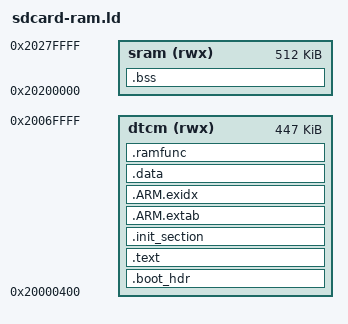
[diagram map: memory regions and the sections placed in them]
/****************************************************************************
 * boards/arm/imxrt/ccx/scripts/sdcard-ram.ld
 *
 * Licensed to the Apache Software Foundation (ASF) under one or more
 * contributor license agreements.  See the NOTICE file distributed with
 * this work for additional information regarding copyright ownership.  The
 * ASF licenses this file to you under the Apache License, Version 2.0 (the
 * "License"); you may not use this file except in compliance with the
 * License.  You may obtain a copy of the License at
 *
 *   http://www.apache.org/licenses/LICENSE-2.0
 *
 * Unless required by applicable law or agreed to in writing, software
 * distributed under the License is distributed on an "AS IS" BASIS, WITHOUT
 * WARRANTIES OR CONDITIONS OF ANY KIND, either express or implied.  See the
 * License for the specific language governing permissions and limitations
 * under the License.
 *
 ****************************************************************************/

/* This script is used for linking NuttX to boot from sdcard/flash and
*  copying the image to RAM using ROM Bootloader functionality.
*/

/* Specify the memory areas */

MEMORY
{
  sram  (rwx) : ORIGIN = 0x20200000, LENGTH = 512K
  dtcm  (rwx) : ORIGIN = 0x20000400, LENGTH = 447k
}

OUTPUT_ARCH(arm)
EXTERN(_vectors)

ENTRY(_stext)

SECTIONS
{	
    .boot_hdr : ALIGN(4)
    {
        __boot_hdr_start__ = ABSOLUTE(.) ;
        KEEP(*(.boot_hdr.ivt))
        . = 0x20 ;
        KEEP(*(.boot_hdr.boot_data))
        __boot_hdr_end__ = ABSOLUTE(.) ;
        . = 0xc00 ;
    } >dtcm
	
    .text :
    {
        _stext = ABSOLUTE(.);
        *(.vectors)
        *(.text .text.*)
        *(.fixup)
        *(.gnu.warning)
        *(.rodata .rodata.*)
        *(.gnu.linkonce.t.*)
        *(.glue_7)
        *(.glue_7t)
        *(.got)
        *(.gcc_except_table)
        *(.gnu.linkonce.r.*)
        _etext = ABSOLUTE(.);
    } > dtcm

    .init_section :
    {
        _sinit = ABSOLUTE(.);
        *(.init_array .init_array.*)
        _einit = ABSOLUTE(.);
    } > dtcm

    .ARM.extab :
    {
        *(.ARM.extab*)
    } > dtcm

    .ARM.exidx :
    {
        __exidx_start = ABSOLUTE(.);
        *(.ARM.exidx*)
        __exidx_end = ABSOLUTE(.);
    } > dtcm

    _eronly = ABSOLUTE(.);

    .data :
    {
        _sdata = ABSOLUTE(.);
        *(.data .data.*)
        *(.gnu.linkonce.d.*)
        CONSTRUCTORS
        . = ALIGN(4);
        _edata = ABSOLUTE(.);
    } > dtcm

    .ramfunc ALIGN(4):
    {
        _sramfuncs = ABSOLUTE(.);
        *(.ramfunc  .ramfunc.*)
        _eramfuncs = ABSOLUTE(.);
    } > dtcm

    _framfuncs = LOADADDR(.ramfunc);

    .bss :
    {
        _sbss = ABSOLUTE(.);
        *(.bss .bss.*)
        *(.gnu.linkonce.b.*)
        *(COMMON)
        . = ALIGN(4);
        _ebss = ABSOLUTE(.);
    } > sram

    /* Stabs debugging sections. */

    .stab 0 : { *(.stab) }
    .stabstr 0 : { *(.stabstr) }
    .stab.excl 0 : { *(.stab.excl) }
    .stab.exclstr 0 : { *(.stab.exclstr) }
    .stab.index 0 : { *(.stab.index) }
    .stab.indexstr 0 : { *(.stab.indexstr) }
    .comment 0 : { *(.comment) }
    .debug_abbrev 0 : { *(.debug_abbrev) }
    .debug_info 0 : { *(.debug_info) }
    .debug_line 0 : { *(.debug_line) }
    .debug_pubnames 0 : { *(.debug_pubnames) }
    .debug_aranges 0 : { *(.debug_aranges) }
}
